# CY8C5888LTI_LP097 register map
File version: 0.1
CY8C58LP
Registers are 8-bit, read-write, no defined reset value unless marked. A register's access mark holds for its fields unless they carry their own. Offsets are from the block's base; lines under a group give offsets from that group; [hi:lo] are bit positions; {n}, {i} and the like mark numbered series; 'fields as' and 'values as' point back to an identical list; <NAME> marks a mode.

## Memory map
0x00000000 BLINK_25HZ
0x00000000 BLINK_CTRL_EN
0x00000000 LED_CTRL
0x00000000 BLINK_05HZ
0x00000000 MOTOR_ON_OFF_1
0x00000000 MY_TIMER_REG
0x00000000 PWM_MOTORS_3
0x00000000 PACER_TIMER
0x00000000 MY_TIMER
0x00000000 FF_STATUS
0x00000000 RESET_FF
0x00000000 PWM_MOTORS
0x00000000 CYCLES_TIMER
0x00000000 UART_RS485 — UART

## BLINK_25HZ
Base 0x00000000
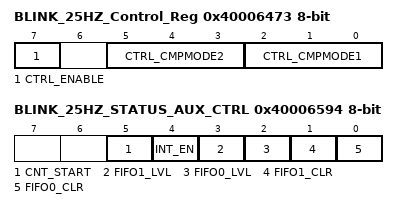
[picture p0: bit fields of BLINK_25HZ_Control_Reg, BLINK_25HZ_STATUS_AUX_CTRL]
0x40006473 BLINK_25HZ_Control_Reg — UDB Control Register - Assigned Control Register Value
  [7] CTRL_ENABLE — Enable the PWM
  [5:3] CTRL_CMPMODE2 — Compare mode 2
  [2:0] CTRL_CMPMODE1 — Compare mode 1
0x40006524 BLINK_25HZ_COMPARE_Reg_ — UDB.D0 - Assigned Compare Value
0x40006594 BLINK_25HZ_STATUS_AUX_CTRL — UDB Auxilliary Control Register
  [5] CNT_START — FIFO0 clear
    0=E_CNT_START0 (Disable counter); 1=E_CNT_START1 (Enable counter)
  [4] INT_EN
    0=E_INT_EN0 (Interrupt disabled); 1=E_INT_EN1 (Interrupt enabled)
  [3] FIFO1_LVL — FIFO level
    0=E_FIFO_LVL_0 (FIFO LVL: input mode: FIFO not full; output mode: FIFO not empty); 1=E_FIFO_LVL_1 (FIFO LVL: input mode: FIFO at least 1/2 empty; output mode: FIFO at least 1/2 full)
  [2] FIFO0_LVL — FIFO level
    values as FIFO1_LVL
  [1] FIFO1_CLR — FIFO1 clear
    0=E_FIFO_CLR_0 (Normal FIFO operation); 1=E_FIFO_CLR_1 (Clear FIFO state)
  [0] FIFO0_CLR — FIFO0 clear
    values as FIFO1_CLR

## BLINK_CTRL_EN
Base 0x00000000
0x40006574 BLINK_CTRL_EN_CONTROL_REG

## LED_CTRL
Base 0x00000000
0x40006577 LED_CTRL_CONTROL_REG

## BLINK_05HZ
Base 0x00000000
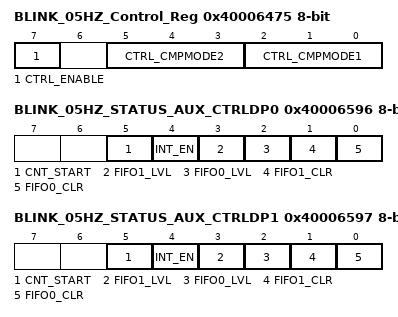
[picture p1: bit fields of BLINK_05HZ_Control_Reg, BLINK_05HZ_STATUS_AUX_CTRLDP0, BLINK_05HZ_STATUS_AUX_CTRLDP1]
0x40006475 BLINK_05HZ_Control_Reg — UDB Control Register - Assigned Control Register Value
  [7] CTRL_ENABLE — Enable the PWM
  [5:3] CTRL_CMPMODE2 — Compare mode 2
  [2:0] CTRL_CMPMODE1 — Compare mode 1
0x40006526 BLINK_05HZ_COMPARE_Reg 16-bit — UDB.D0 - Assigned Compare Value
0x40006596 BLINK_05HZ_STATUS_AUX_CTRLDP0 — UDB Auxilliary Control Register
  [5] CNT_START — FIFO0 clear
    0=E_CNT_START0 (Disable counter); 1=E_CNT_START1 (Enable counter)
  [4] INT_EN
    0=E_INT_EN0 (Interrupt disabled); 1=E_INT_EN1 (Interrupt enabled)
  [3] FIFO1_LVL — FIFO level
    0=E_FIFO_LVL_0 (FIFO LVL: input mode: FIFO not full; output mode: FIFO not empty); 1=E_FIFO_LVL_1 (FIFO LVL: input mode: FIFO at least 1/2 empty; output mode: FIFO at least 1/2 full)
  [2] FIFO0_LVL — FIFO level
    values as FIFO1_LVL
  [1] FIFO1_CLR — FIFO1 clear
    0=E_FIFO_CLR_0 (Normal FIFO operation); 1=E_FIFO_CLR_1 (Clear FIFO state)
  [0] FIFO0_CLR — FIFO0 clear
    values as FIFO1_CLR
0x40006597 BLINK_05HZ_STATUS_AUX_CTRLDP1 — UDB Auxilliary Control Register
  fields as BLINK_05HZ_STATUS_AUX_CTRLDP0

## MOTOR_ON_OFF_1
Base 0x00000000
0x40006471 MOTOR_ON_OFF_1_CONTROL_REG

## MY_TIMER_REG
Base 0x00000000
0x40006576 MY_TIMER_REG_CONTROL_REG

## PWM_MOTORS_3
Base 0x00000000
0x40006421 PWM_MOTORS_3__COMPARE1 — UDB.D0 - Assigned Compare1 Value
0x40006431 PWM_MOTORS_3__COMPARE2 — UDB.D1 - Assigned Compare2 Value
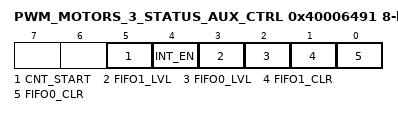
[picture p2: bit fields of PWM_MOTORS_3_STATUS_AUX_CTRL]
0x40006491 PWM_MOTORS_3_STATUS_AUX_CTRL — UDB Auxilliary Control Register
  [5] CNT_START — FIFO0 clear
    0=E_CNT_START0 (Disable counter); 1=E_CNT_START1 (Enable counter)
  [4] INT_EN
    0=E_INT_EN0 (Interrupt disabled); 1=E_INT_EN1 (Interrupt enabled)
  [3] FIFO1_LVL — FIFO level
    0=E_FIFO_LVL_0 (FIFO LVL: input mode: FIFO not full; output mode: FIFO not empty); 1=E_FIFO_LVL_1 (FIFO LVL: input mode: FIFO at least 1/2 empty; output mode: FIFO at least 1/2 full)
  [2] FIFO0_LVL — FIFO level
    values as FIFO1_LVL
  [1] FIFO1_CLR — FIFO1 clear
    0=E_FIFO_CLR_0 (Normal FIFO operation); 1=E_FIFO_CLR_1 (Clear FIFO state)
  [0] FIFO0_CLR — FIFO0 clear
    values as FIFO1_CLR
